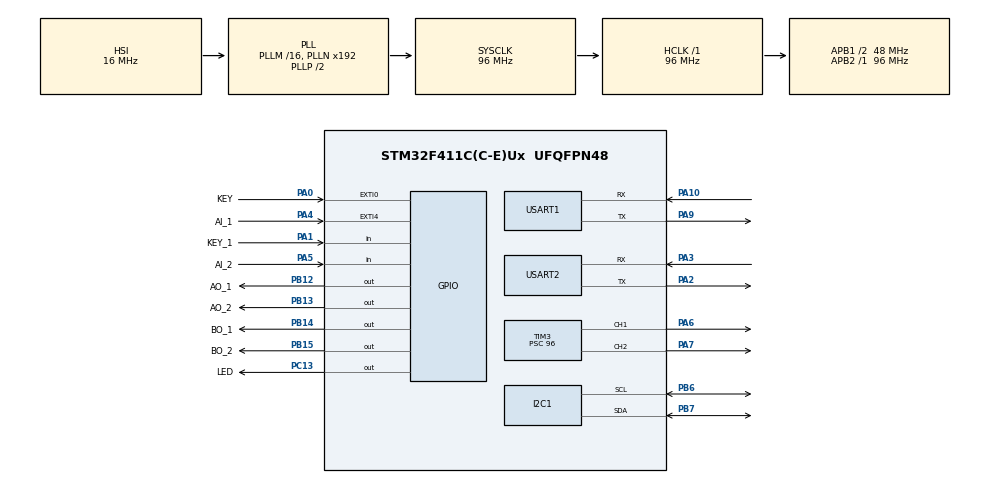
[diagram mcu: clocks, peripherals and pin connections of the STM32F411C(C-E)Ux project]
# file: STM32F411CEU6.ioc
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FREERTOS.Tasks01=defaultTask,0,128,StartDefaultTask,As weak,NULL,Dynamic,NULL,NULL;INV,0,128,inv_task,As weak,NULL,Dynamic,NULL,NULL
I2C1.I2C_Mode=I2C_Fast
Mcu.Family=STM32F4
Mcu.Name=STM32F411C(C-E)Ux
Mcu.Package=UFQFPN48
NVIC.EXTI0_IRQn=true\:5\:0\:false\:false\:true\:true\:true\:true\:true
NVIC.PriorityGroup=NVIC_PRIORITYGROUP_4
NVIC.USART1_IRQn=true\:5\:0\:true\:false\:true\:true\:true\:true\:true
NVIC.USART2_IRQn=true\:5\:0\:true\:false\:true\:true\:true\:true\:true
PA0-WKUP.GPIO_Label=KEY
PA0-WKUP.GPIO_PuPd=GPIO_PULLUP
PA0-WKUP.Signal=GPXTI0
PA1.GPIO_Label=KEY_1
PA1.GPIO_PuPd=GPIO_PULLUP
PA1.Signal=GPIO_Input
PA10.Mode=Asynchronous
PA10.Signal=USART1_RX
PA13.Mode=Serial_Wire
PA13.Signal=SYS_JTMS-SWDIO
PA14.Mode=Serial_Wire
PA14.Signal=SYS_JTCK-SWCLK
PA2.Mode=Asynchronous
PA2.Signal=USART2_TX
PA3.Mode=Asynchronous
PA3.Signal=USART2_RX
PA4.GPIO_Label=AI_1
PA4.GPIO_PuPd=GPIO_PULLUP
PA4.Signal=GPXTI4
PA5.GPIO_Label=AI_2
PA5.GPIO_PuPd=GPIO_PULLUP
PA5.Signal=GPIO_Input
PA6.Signal=S_TIM3_CH1
PA7.Signal=S_TIM3_CH2
PA9.Mode=Asynchronous
PA9.Signal=USART1_TX
PB12.GPIO_Label=AO_1
PB12.Signal=GPIO_Output
PB13.GPIO_Label=AO_2
PB13.Signal=GPIO_Output
PB14.GPIO_Label=BO_1
PB14.Signal=GPIO_Output
PB15.GPIO_Label=BO_2
PB15.Signal=GPIO_Output
PB6.Mode=I2C
PB6.Signal=I2C1_SCL
PB7.Mode=I2C
PB7.Signal=I2C1_SDA
PC13-ANTI_TAMP.GPIO_Label=LED
PC13-ANTI_TAMP.Signal=GPIO_Output
PC14-OSC32_IN.Mode=LSE-External-Oscillator
PC14-OSC32_IN.Signal=RCC_OSC32_IN
PC15-OSC32_OUT.Mode=LSE-External-Oscillator
PC15-OSC32_OUT.Signal=RCC_OSC32_OUT
PH0\ -\ OSC_IN.Mode=HSE-External-Oscillator
PH0\ -\ OSC_IN.Signal=RCC_OSC_IN
PH1\ -\ OSC_OUT.Mode=HSE-External-Oscillator
PH1\ -\ OSC_OUT.Signal=RCC_OSC_OUT
ProjectManager.HeapSize=0x200
ProjectManager.StackSize=0x400
ProjectManager.TargetToolchain=MDK-ARM V5.32
RCC.AHBFreq_Value=96000000
RCC.APB1CLKDivider=RCC_HCLK_DIV2
RCC.APB1Freq_Value=48000000
RCC.APB1TimFreq_Value=96000000
RCC.APB2Freq_Value=96000000
RCC.APB2TimFreq_Value=96000000
RCC.CortexFreq_Value=96000000
RCC.HCLKFreq_Value=96000000
RCC.HSE_VALUE=25000000
RCC.HSI_VALUE=16000000
RCC.SYSCLKFreq_VALUE=96000000
RCC.SYSCLKSource=RCC_SYSCLKSOURCE_PLLCLK
RCC.VCOOutputFreq_Value=192000000
SH.S_TIM3_CH1.0=TIM3_CH1,PWM Generation1 CH1
SH.S_TIM3_CH2.0=TIM3_CH2,PWM Generation2 CH2
TIM3.Channel-PWM\ Generation1\ CH1=TIM_CHANNEL_1
TIM3.Channel-PWM\ Generation2\ CH2=TIM_CHANNEL_2
TIM3.Period=19999
TIM3.Prescaler=96
USART1.VirtualMode=VM_ASYNC
USART2.VirtualMode=VM_ASYNC
VP_FREERTOS_VS_CMSIS_V1.Mode=CMSIS_V1
board=custom

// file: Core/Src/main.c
/* USER CODE BEGIN Header */
/**
  ******************************************************************************
  * @file           : main.c
  * @brief          : Main program body
  ******************************************************************************
  * @attention
  *
  * Copyright (c) 2022 STMicroelectronics.
  * All rights reserved.
  *
  * This software is licensed under terms that can be found in the LICENSE file
  * in the root directory of this software component.
  * If no LICENSE file comes with this software, it is provided AS-IS.
  *
  ******************************************************************************
  */
/* USER CODE END Header */
#include "main.h"
#include "cmsis_os.h"
#include "i2c.h"
#include "tim.h"
#include "usart.h"
#include "gpio.h"

/* USER CODE BEGIN Includes */
#include "bsp_usart.h"

#include "default_task.h"
#include "inv_task.h"
/* USER CODE END Includes */

void SystemClock_Config(void);
void MX_FREERTOS_Init(void);

int main(void)
{

  /* MCU Configuration--------------------------------------------------------*/

  /* Reset of all peripherals, Initializes the Flash interface and the Systick. */
  HAL_Init();

  /* Configure the system clock */
  SystemClock_Config();

  /* Initialize all configured peripherals */
  MX_GPIO_Init();
  MX_USART1_UART_Init();
  MX_USART2_UART_Init();
  MX_TIM3_Init();
  MX_I2C1_Init();
  /* USER CODE BEGIN 2 */

  USART_Init();
  /* USER CODE END 2 */

  /* Call init function for freertos objects (in freertos.c) */
  MX_FREERTOS_Init();

  /* Start scheduler */
  osKernelStart();

  /* We should never get here as control is now taken by the scheduler */
  /* Infinite loop */
  while (1)
  {

  }
}

void SystemClock_Config(void)
{
  RCC_OscInitTypeDef RCC_OscInitStruct = {0};
  RCC_ClkInitTypeDef RCC_ClkInitStruct = {0};

  /** Configure the main internal regulator output voltage
  */
  __HAL_RCC_PWR_CLK_ENABLE();
  __HAL_PWR_VOLTAGESCALING_CONFIG(PWR_REGULATOR_VOLTAGE_SCALE1);

  /** Initializes the RCC Oscillators according to the specified parameters
  * in the RCC_OscInitTypeDef structure.
  */
  RCC_OscInitStruct.OscillatorType = RCC_OSCILLATORTYPE_HSI;
  RCC_OscInitStruct.HSIState = RCC_HSI_ON;
  RCC_OscInitStruct.HSICalibrationValue = RCC_HSICALIBRATION_DEFAULT;
  RCC_OscInitStruct.PLL.PLLState = RCC_PLL_ON;
  RCC_OscInitStruct.PLL.PLLSource = RCC_PLLSOURCE_HSI;
  RCC_OscInitStruct.PLL.PLLM = 16;
  RCC_OscInitStruct.PLL.PLLN = 192;
  RCC_OscInitStruct.PLL.PLLP = RCC_PLLP_DIV2;
  RCC_OscInitStruct.PLL.PLLQ = 4;
  if (HAL_RCC_OscConfig(&RCC_OscInitStruct) != HAL_OK)
  {
    Error_Handler();
  }

  /** Initializes the CPU, AHB and APB buses clocks
  */
  RCC_ClkInitStruct.ClockType = RCC_CLOCKTYPE_HCLK|RCC_CLOCKTYPE_SYSCLK
                              |RCC_CLOCKTYPE_PCLK1|RCC_CLOCKTYPE_PCLK2;
  RCC_ClkInitStruct.SYSCLKSource = RCC_SYSCLKSOURCE_PLLCLK;
  RCC_ClkInitStruct.AHBCLKDivider = RCC_SYSCLK_DIV1;
  RCC_ClkInitStruct.APB1CLKDivider = RCC_HCLK_DIV2;
  RCC_ClkInitStruct.APB2CLKDivider = RCC_HCLK_DIV1;

  if (HAL_RCC_ClockConfig(&RCC_ClkInitStruct, FLASH_LATENCY_3) != HAL_OK)
  {
    Error_Handler();
  }
}

void Error_Handler(void)
{
  __disable_irq();
  while (1)
  {
  }
}

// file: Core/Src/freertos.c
/* USER CODE BEGIN Header */
/**
  ******************************************************************************
  * File Name          : freertos.c
  * Description        : Code for freertos applications
  ******************************************************************************
  * @attention
  *
  * Copyright (c) 2023 STMicroelectronics.
  * All rights reserved.
  *
  * This software is licensed under terms that can be found in the LICENSE file
  * in the root directory of this software component.
  * If no LICENSE file comes with this software, it is provided AS-IS.
  *
  ******************************************************************************
  */
/* USER CODE END Header */

#include "FreeRTOS.h"
#include "task.h"
#include "main.h"
#include "cmsis_os.h"

osThreadId defaultTaskHandle;
osThreadId INVHandle;

void StartDefaultTask(void const * argument);
void inv_task(void const * argument);

void MX_FREERTOS_Init(void); /* (MISRA C 2004 rule 8.1) */

/* GetIdleTaskMemory prototype (linked to static allocation support) */
void vApplicationGetIdleTaskMemory( StaticTask_t **ppxIdleTaskTCBBuffer, StackType_t **ppxIdleTaskStackBuffer, uint32_t *pulIdleTaskStackSize );

/* USER CODE BEGIN GET_IDLE_TASK_MEMORY */
static StaticTask_t xIdleTaskTCBBuffer;
static StackType_t xIdleStack[configMINIMAL_STACK_SIZE];

void vApplicationGetIdleTaskMemory( StaticTask_t **ppxIdleTaskTCBBuffer, StackType_t **ppxIdleTaskStackBuffer, uint32_t *pulIdleTaskStackSize )
{
  *ppxIdleTaskTCBBuffer = &xIdleTaskTCBBuffer;
  *ppxIdleTaskStackBuffer = &xIdleStack[0];
  *pulIdleTaskStackSize = configMINIMAL_STACK_SIZE;
  /* place for user code */
}
/* USER CODE END GET_IDLE_TASK_MEMORY */

void MX_FREERTOS_Init(void) {

  /* Create the thread(s) */
  /* definition and creation of defaultTask */
  osThreadDef(defaultTask, StartDefaultTask, osPriorityNormal, 0, 128);
  defaultTaskHandle = osThreadCreate(osThread(defaultTask), NULL);

  /* definition and creation of INV */
  osThreadDef(INV, inv_task, osPriorityNormal, 0, 128);
  INVHandle = osThreadCreate(osThread(INV), NULL);

}

__weak void StartDefaultTask(void const * argument)
{
  for(;;)
  {
    osDelay(1);
  }
}

__weak void inv_task(void const * argument)
{
  for(;;)
  {
    osDelay(1);
  }
}
